AUTOSAR XML (schema 314)
package /VehicleProject
  system System: fibex-element=[CAN00, EPAS, EPAS__CAN00_Rx, EPAS__CAN00_Tx, ABS2__CAN00, BCM1__CAN00, DiagFuncReqFT__CAN00, DiagPhysReqToEPAS__CAN00, DiagRespFromEPAS__CAN00, ECM1__CAN00, EPAS1__CAN00, EPAS2__CAN00, GliwaMaster__CAN00, GliwaSlave__CAN00, NMmBCM__CAN00, NMmEPAS__CAN00, XcpMaster__CAN00, XcpSlave__CAN00, ABS2__CAN00, BCM1__CAN00, ECM1__CAN00, EPAS1__CAN00, EPAS2__CAN00, GliwaMaster__CAN00, GliwaSlave__CAN00, NMmBCM__CAN00, NMmEPAS__CAN00, XcpMaster__CAN00, XcpSlave__CAN00, DiagFuncReqFT__CAN00, DiagPhysReqToEPAS__CAN00, DiagRespFromEPAS__CAN00, DiagFuncReqFT_Tp__CAN00, DiagPhysReqToEPAS_Tp__CAN00, DiagRespFromEPAS_Tp__CAN00, BCM_Key_Sta__BCM1__CAN00, CAN_N__ECM1__CAN00, Elect_PWR_Consumpt__EPAS2__CAN00, EpasFailed__EPAS2__CAN00, LV_CAN_N_ERR__ECM1__CAN00, Rel_Steer_Wheel_Ang__EPAS2__CAN00, Rel_Steer_Wheel_Ang_Validity__EPAS2__CAN00, SAS_Angle__EPAS1__CAN00, SAS_CAL__EPAS1__CAN00, SAS_CheckSum__EPAS1__CAN00, SAS_Init__EPAS1__CAN00, SAS_MsgCount__EPAS1__CAN00, SAS_OK__EPAS1__CAN00, Steering_Torque__EPAS2__CAN00, Steering_Torque_V__EPAS2__CAN00, VehSpeed__ABS2__CAN00]
package /Cluster
  can cluster CAN00: protocol-name=CAN  # Haitec_LC_HS2_CAN
    physical channel CHNL
      frame ABS2__CAN00: id 0x360, to EPAS, frame-length=8, can-addressing-mode=STANDARD
        pdu ABS2__CAN00: length=64, cyclic-timing={repeating-time=0.01, starting-time=0}, minimum-delay=0, transmission-mode-false-timing=cyclic-timing={repeating-time=0.01, starting-time=0}
          signal VehSpeed__ABS2__CAN00: start 7, 12 bit, big-endian, data-type=DT_VehSpeed, init-value=C_VehSpeed, transfer-property=PENDING, to EPAS
      frame BCM1__CAN00: id 0x420, to EPAS, frame-length=8, can-addressing-mode=STANDARD
        pdu BCM1__CAN00: length=64, minimum-delay=0
          signal BCM_Key_Sta__BCM1__CAN00: start 7, 2 bit, big-endian, data-type=DT_BCM_Key_Sta, init-value=C_BCM_Key_Sta, transfer-property=PENDING, to EPAS
      frame DiagFuncReqFT__CAN00: id 0x7D0, to EPAS, frame-length=8, can-addressing-mode=STANDARD
        n pdu DiagFuncReqFT_Tp__CAN00: length=64
      frame DiagPhysReqToEPAS__CAN00: id 0x772, to EPAS, frame-length=8, can-addressing-mode=STANDARD
        n pdu DiagPhysReqToEPAS_Tp__CAN00: length=64
      frame DiagRespFromEPAS__CAN00: id 0x7B2, from EPAS, frame-length=8, can-addressing-mode=STANDARD
        n pdu DiagRespFromEPAS_Tp__CAN00: length=64
      frame ECM1__CAN00: id 0x316, to EPAS, frame-length=8, can-addressing-mode=STANDARD
        pdu ECM1__CAN00: length=64, cyclic-timing={repeating-time=0.01, starting-time=0}, minimum-delay=0, transmission-mode-false-timing=cyclic-timing={repeating-time=0.01, starting-time=0}
          signal LV_CAN_N_ERR__ECM1__CAN00: start 1, 1 bit, big-endian, data-type=DT_LV_CAN_N_ERR, init-value=C_LV_CAN_N_ERR, transfer-property=PENDING, to EPAS
          signal CAN_N__ECM1__CAN00: start 23, 16 bit, big-endian, data-type=DT_CAN_N, init-value=C_CAN_N, transfer-property=PENDING, to EPAS
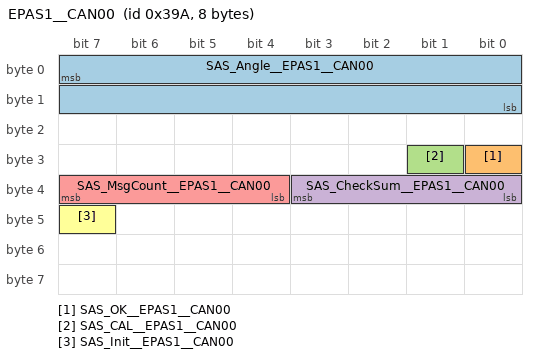
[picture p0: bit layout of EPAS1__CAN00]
      frame EPAS1__CAN00: id 0x39A, from EPAS, frame-length=8, can-addressing-mode=STANDARD
        pdu EPAS1__CAN00: length=64, cyclic-timing={repeating-time=0.01, starting-time=0}, minimum-delay=0, transmission-mode-false-timing=cyclic-timing={repeating-time=0.01, starting-time=0}
          signal SAS_Angle__EPAS1__CAN00: start 7, 16 bit, big-endian, data-type=DT_SAS_Angle, init-value=C_SAS_Angle, transfer-property=PENDING
          signal SAS_OK__EPAS1__CAN00: start 24, 1 bit, big-endian, data-type=DT_SAS_OK, init-value=C_SAS_OK, transfer-property=PENDING
          signal SAS_CAL__EPAS1__CAN00: start 25, 1 bit, big-endian, data-type=DT_SAS_CAL, init-value=C_SAS_CAL, transfer-property=PENDING
          signal SAS_CheckSum__EPAS1__CAN00: start 35, 4 bit, big-endian, data-type=DT_SAS_CheckSum, init-value=C_SAS_CheckSum, transfer-property=PENDING
          signal SAS_MsgCount__EPAS1__CAN00: start 39, 4 bit, big-endian, data-type=DT_SAS_MsgCount, init-value=C_SAS_MsgCount, transfer-property=PENDING
          signal SAS_Init__EPAS1__CAN00: start 47, 1 bit, big-endian, data-type=DT_SAS_Init, init-value=C_SAS_Init, transfer-property=PENDING
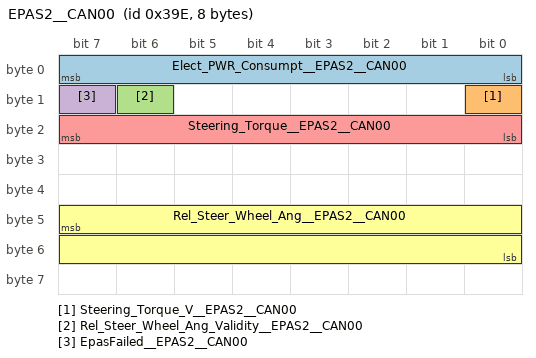
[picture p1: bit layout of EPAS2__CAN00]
      frame EPAS2__CAN00: id 0x39E, from EPAS, frame-length=8, can-addressing-mode=STANDARD
        pdu EPAS2__CAN00: length=64, cyclic-timing={repeating-time=0.01, starting-time=0}, minimum-delay=0, transmission-mode-false-timing=cyclic-timing={repeating-time=0.01, starting-time=0}
          signal Elect_PWR_Consumpt__EPAS2__CAN00: start 7, 8 bit, big-endian, data-type=DT_Elect_PWR_Consumpt, init-value=C_Elect_PWR_Consumpt, transfer-property=PENDING
          signal Steering_Torque_V__EPAS2__CAN00: start 8, 1 bit, big-endian, data-type=DT_Steering_Torque_V, init-value=C_Steering_Torque_V, transfer-property=PENDING
          signal Rel_Steer_Wheel_Ang_Validity__EPAS2__CAN00: start 14, 1 bit, big-endian, data-type=DT_Rel_Steer_Wheel_Ang_Validity, init-value=C_Rel_Steer_Wheel_Ang_Validity, transfer-property=PENDING
          signal EpasFailed__EPAS2__CAN00: start 15, 1 bit, big-endian, data-type=DT_EpasFailed, init-value=C_EpasFailed, transfer-property=PENDING
          signal Steering_Torque__EPAS2__CAN00: start 23, 8 bit, big-endian, data-type=DT_Steering_Torque, init-value=C_Steering_Torque, transfer-property=PENDING
          signal Rel_Steer_Wheel_Ang__EPAS2__CAN00: start 47, 16 bit, big-endian, data-type=DT_Rel_Steer_Wheel_Ang, init-value=C_Rel_Steer_Wheel_Ang, transfer-property=PENDING
      frame GliwaMaster__CAN00: id 0x7F0, to EPAS, frame-length=8, can-addressing-mode=STANDARD
        pdu GliwaMaster__CAN00: length=64
      frame GliwaSlave__CAN00: id 0x7F1, from EPAS, frame-length=8, can-addressing-mode=STANDARD
        pdu GliwaSlave__CAN00: length=64
      frame NMmBCM__CAN00: id 0x700, to EPAS, frame-length=8, can-addressing-mode=STANDARD
        pdu NMmBCM__CAN00: length=64
      frame NMmEPAS__CAN00: id 0x707, from EPAS, frame-length=8, can-addressing-mode=STANDARD
        pdu NMmEPAS__CAN00: length=64
      frame XcpMaster__CAN00: id 0x695, to EPAS, frame-length=8, can-addressing-mode=STANDARD
        pdu XcpMaster__CAN00: length=64
      frame XcpSlave__CAN00: id 0x6E5, from EPAS, frame-length=8, can-addressing-mode=STANDARD
        pdu XcpSlave__CAN00: length=64
      pdu triggering PT_DiagFuncReqFT: pdu=DiagFuncReqFT__CAN00, to EPAS
      pdu triggering PT_DiagPhysReqToEPAS: pdu=DiagPhysReqToEPAS__CAN00, to EPAS
      pdu triggering PT_DiagRespFromEPAS: pdu=DiagRespFromEPAS__CAN00, from EPAS
      tp-channels:
        addressing-format=STANDARD, data-pdu=DiagFuncReqFT_Tp__CAN00, multicast-addressing=true, padding-activation=true, target=CN_CAN00, tp-sdu=DiagFuncReqFT__CAN00
        addressing-format=STANDARD, data-pdu=DiagRespFromEPAS_Tp__CAN00, flow-control-pdu=DiagPhysReqToEPAS_Tp__CAN00, multicast-addressing=false, padding-activation=true, source=CN_CAN00, tp-sdu=DiagRespFromEPAS__CAN00
        addressing-format=STANDARD, data-pdu=DiagPhysReqToEPAS_Tp__CAN00, flow-control-pdu=DiagRespFromEPAS_Tp__CAN00, multicast-addressing=false, padding-activation=true, target=CN_CAN00, tp-sdu=DiagPhysReqToEPAS__CAN00
package /ECU
  ecu instance EPAS: associated-i-pdu-group=[EPAS__CAN00_Rx, EPAS__CAN00_Tx], com-processing-period=0.001
    can communication controller CT_CAN00
    communication connector CN_CAN00: channel=CHNL, comm-controller=CT_CAN00
package /IPDUGroup
  i pdu group EPAS__CAN00_Rx: communication-direction=IN, i-pdu=[ABS2__CAN00, BCM1__CAN00, ECM1__CAN00]
  i pdu group EPAS__CAN00_Tx: communication-direction=OUT, i-pdu=[EPAS1__CAN00, EPAS2__CAN00]
package /PDU
  dcm i pdu DiagFuncReqFT__CAN00: length=64
  dcm i pdu DiagPhysReqToEPAS__CAN00: length=64
  dcm i pdu DiagRespFromEPAS__CAN00: length=64
package /DataType
  7 x boolean type:
    DT_EpasFailed: compu {0=Cx0_Not_Failed (Not Failed), 1=Cx1_Failed; unit enum}
    DT_LV_CAN_N_ERR: compu {0=Cx0_OK, 1=Cx1_Fail; unit enum}
    DT_Rel_Steer_Wheel_Ang_Validity: compu {0=Cx0_Invalid, 1=Cx1_Valid}
    DT_SAS_CAL: compu {0=Cx0_Not_Calibrated (Not Calibrated), 1=Cx1_Calibrated; unit enum}
    DT_SAS_Init: compu {0=Cx0_Initialization_Not_Finished (Initialization Not Finished), 1=Cx1_Initialization_Finished (Initialization Finished); unit enum}
    DT_SAS_OK: compu {0=Cx0_Invalid, 1=Cx1_Valid; unit enum}
    DT_Steering_Torque_V: compu {0=Cx0_Not_Failed (Not Failed), 1=Cx1_Failed; unit enum}
  9 x integer type, all with lower-limit=0:
    DT_BCM_Key_Sta: compu {0=Cx0_Lock, 1=Cx1_Acc, 2=Cx2_On, 3=Cx3_Start; unit enum}, upper-limit=3
    DT_CAN_N: compu {phys=raw*0.125; unit rpm}, upper-limit=65535
    DT_Elect_PWR_Consumpt: compu {phys=raw*0.5; unit amp}, upper-limit=254
    DT_Rel_Steer_Wheel_Ang: compu {phys=raw*0.1-2000; unit deg}, upper-limit=40000
    DT_SAS_Angle: compu {phys=raw*0.1-900; unit deg}, upper-limit=18000
    DT_SAS_CheckSum: compu {; unit cnt}, upper-limit=15
    DT_SAS_MsgCount: compu {; unit cnt}, upper-limit=15
    DT_Steering_Torque: compu {phys=raw*0.1794-22.78; unit nm}, upper-limit=255
    DT_VehSpeed: compu {phys=raw*0.125; unit kph}, upper-limit=2047
package /DataType/Unit
  7 x unit:
    U_amp: display-name=amp
    U_cnt: display-name=cnt
    U_deg: display-name=deg
    U_enum: display-name=enum
    U_kph: display-name=kph
    U_nm: display-name=nm
    U_rpm: display-name=rpm
package /Constant
  16 x constant specification:
    C_EpasFailed
      value:
        boolean literal C_EpasFailed: type=DT_EpasFailed, value=false
    C_LV_CAN_N_ERR
      value:
        boolean literal C_LV_CAN_N_ERR: type=DT_LV_CAN_N_ERR, value=false
    C_Rel_Steer_Wheel_Ang_Validity
      value:
        boolean literal C_Rel_Steer_Wheel_Ang_Validity: type=DT_Rel_Steer_Wheel_Ang_Validity, value=false
    C_SAS_CAL
      value:
        boolean literal C_SAS_CAL: type=DT_SAS_CAL, value=false
    C_SAS_Init
      value:
        boolean literal C_SAS_Init: type=DT_SAS_Init, value=false
    C_SAS_OK
      value:
        boolean literal C_SAS_OK: type=DT_SAS_OK, value=true
    C_Steering_Torque_V
      value:
        boolean literal C_Steering_Torque_V: type=DT_Steering_Torque_V, value=false
    C_BCM_Key_Sta
      value:
        integer literal C_BCM_Key_Sta: type=DT_BCM_Key_Sta, value=0
    C_CAN_N
      value:
        integer literal C_CAN_N: type=DT_CAN_N, value=0
    C_Elect_PWR_Consumpt
      value:
        integer literal C_Elect_PWR_Consumpt: type=DT_Elect_PWR_Consumpt, value=0
    C_Rel_Steer_Wheel_Ang
      value:
        integer literal C_Rel_Steer_Wheel_Ang: type=DT_Rel_Steer_Wheel_Ang, value=20000
    C_SAS_Angle
      value:
        integer literal C_SAS_Angle: type=DT_SAS_Angle, value=9001
    C_SAS_CheckSum
      value:
        integer literal C_SAS_CheckSum: type=DT_SAS_CheckSum, value=0
    C_SAS_MsgCount
      value:
        integer literal C_SAS_MsgCount: type=DT_SAS_MsgCount, value=0
    C_Steering_Torque
      value:
        integer literal C_Steering_Torque: type=DT_Steering_Torque, value=128
    C_VehSpeed
      value:
        integer literal C_VehSpeed: type=DT_VehSpeed, value=0
